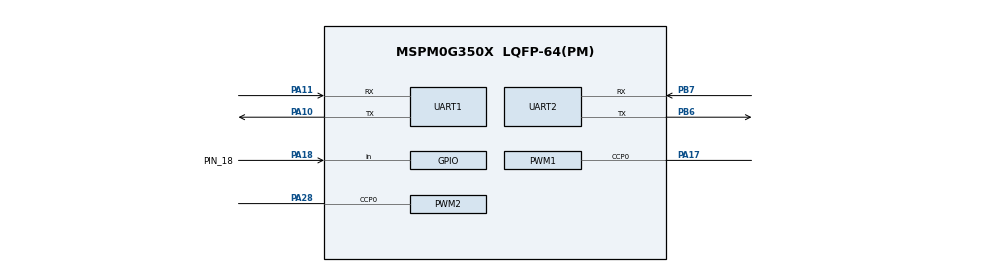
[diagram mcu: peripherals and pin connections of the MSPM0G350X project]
/**
 * @cliArgs --device "MSPM0G350X" --package "LQFP-64(PM)" --part "Default" --product "mspm0_sdk@1.30.00.03"
 * @versions {"tool":"1.19.0+3426"}
 */

/**
 * Import the modules used in this configuration.
 */
const GPIO    = scripting.addModule("/ti/driverlib/GPIO", {}, false);
const GPIO1   = GPIO.addInstance();
const GPIO2   = GPIO.addInstance();
const GPIO3   = GPIO.addInstance();
const PWM     = scripting.addModule("/ti/driverlib/PWM", {}, false);
const PWM1    = PWM.addInstance();
const PWM2    = PWM.addInstance();
const SYSCTL  = scripting.addModule("/ti/driverlib/SYSCTL");
const SYSTICK = scripting.addModule("/ti/driverlib/SYSTICK");
const TIMER   = scripting.addModule("/ti/driverlib/TIMER", {}, false);
const TIMER1  = TIMER.addInstance();
const UART    = scripting.addModule("/ti/driverlib/UART", {}, false);
const UART1   = UART.addInstance();
const UART2   = UART.addInstance();

/**
 * Write custom configuration values to the imported modules.
 */
const gate7  = system.clockTree["MFCLKGATE"];
gate7.enable = true;

GPIO1.$name                              = "LED1";
GPIO1.associatedPins[0].internalResistor = "PULL_DOWN";
GPIO1.associatedPins[0].$name            = "PIN_22";
GPIO1.associatedPins[0].assignedPort     = "PORTB";
GPIO1.associatedPins[0].assignedPin      = "22";

const Board = scripting.addModule("/ti/driverlib/Board", {}, false);

GPIO2.$name                              = "KEY";
GPIO2.port                               = "PORTA";
GPIO2.associatedPins[0].$name            = "PIN_18";
GPIO2.associatedPins[0].direction        = "INPUT";
GPIO2.associatedPins[0].assignedPin      = "18";
GPIO2.associatedPins[0].internalResistor = "PULL_DOWN";
GPIO2.associatedPins[0].interruptEn      = true;
GPIO2.associatedPins[0].polarity         = "RISE";
GPIO2.associatedPins[0].pin.$assign      = "PA18";

GPIO3.$name                          = "OLED";
GPIO3.associatedPins.create(2);
GPIO3.associatedPins[0].$name        = "SDA";
GPIO3.associatedPins[0].assignedPort = "PORTB";
GPIO3.associatedPins[0].assignedPin  = "8";
GPIO3.associatedPins[1].$name        = "SCL";
GPIO3.associatedPins[1].assignedPort = "PORTB";
GPIO3.associatedPins[1].assignedPin  = " 9";

PWM1.ccIndex                            = [0];
PWM1.$name                              = "PWM";
PWM1.clockDivider                       = 8;
PWM1.timerCount                         = 400;
PWM1.timerStartTimer                    = true;
PWM1.clockPrescale                      = 200;
PWM1.peripheral.$assign                 = "TIMG7";
PWM1.peripheral.ccp0Pin.$assign         = "PA17";
PWM1.PWM_CHANNEL_0.$name                = "ti_driverlib_pwm_PWMTimerCC0";
PWM1.PWM_CHANNEL_0.invert               = true;
PWM1.ccp0PinConfig.direction            = scripting.forceWrite("OUTPUT");
PWM1.ccp0PinConfig.hideOutputInversion  = scripting.forceWrite(false);
PWM1.ccp0PinConfig.onlyInternalResistor = scripting.forceWrite(false);
PWM1.ccp0PinConfig.passedPeripheralType = scripting.forceWrite("Digital");
PWM1.ccp0PinConfig.$name                = "ti_driverlib_gpio_GPIOPinGeneric2";

PWM2.$name                      = "PWM_1";
PWM2.ccIndex                    = [0];
PWM2.clockDivider               = 8;
PWM2.timerCount                 = 400;
PWM2.timerStartTimer            = true;
PWM2.clockPrescale              = 200;
PWM2.peripheral.$assign         = "TIMA1";
PWM2.peripheral.ccp0Pin.$assign = "PA28";
PWM2.PWM_CHANNEL_0.$name        = "ti_driverlib_pwm_PWMTimerCC0_COPY";
PWM2.PWM_CHANNEL_0.invert       = true;
PWM2.ccp0PinConfig.$name        = "ti_driverlib_gpio_GPIOPinGeneric2_COPY";

SYSCTL.forceDefaultClkConfig = true;
SYSCTL.clockTreeEn           = true;

SYSTICK.periodEnable      = true;
SYSTICK.systickEnable     = true;
SYSTICK.interruptPriority = "0";
SYSTICK.period            = 32;

TIMER1.$name              = "TIMER_0";
TIMER1.timerClkDiv        = 8;
TIMER1.timerStartTimer    = true;
TIMER1.timerMode          = "PERIODIC";
TIMER1.interrupts         = ["ZERO"];
TIMER1.timerClkPrescale   = 10;
TIMER1.interruptPriority  = "0";
TIMER1.timerPeriod        = "80ms";
TIMER1.peripheral.$assign = "TIMG0";

UART1.$name                    = "UART_0";
UART1.uartClkSrc               = "MFCLK";
UART1.enabledInterrupts        = ["RX"];
UART1.targetBaudRate           = 115200;
UART1.interruptPriority        = "2";
UART1.peripheral.$assign       = "UART0";
UART1.peripheral.rxPin.$assign = "PA11";
UART1.peripheral.txPin.$assign = "PA10";
UART1.txPinConfig.$name        = "ti_driverlib_gpio_GPIOPinGeneric0";
UART1.rxPinConfig.$name        = "ti_driverlib_gpio_GPIOPinGeneric1";

UART2.$name                    = "UART_1";
UART2.uartClkSrc               = "MFCLK";
UART2.enabledInterrupts        = ["RX"];
UART2.peripheral.rxPin.$assign = "PB7";
UART2.peripheral.txPin.$assign = "PB6";
UART2.txPinConfig.$name        = "ti_driverlib_gpio_GPIOPinGeneric3";
UART2.rxPinConfig.$name        = "ti_driverlib_gpio_GPIOPinGeneric4";

/**
 * Pinmux solution for unlocked pins/peripherals. This ensures that minor changes to the automatic solver in a future
 * version of the tool will not impact the pinmux you originally saw.  These lines can be completely deleted in order to
 * re-solve from scratch.
 */
GPIO1.associatedPins[0].pin.$suggestSolution = "PB22";
Board.peripheral.$suggestSolution            = "DEBUGSS";
Board.peripheral.swclkPin.$suggestSolution   = "PA20";
Board.peripheral.swdioPin.$suggestSolution   = "PA19";
GPIO3.associatedPins[0].pin.$suggestSolution = "PB8";
GPIO3.associatedPins[1].pin.$suggestSolution = "PB9";
UART2.peripheral.$suggestSolution            = "UART1";
